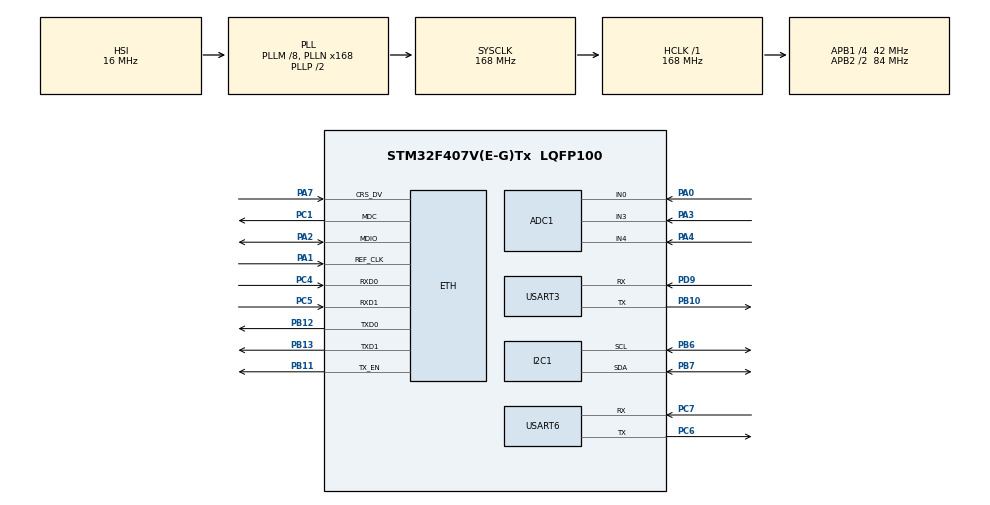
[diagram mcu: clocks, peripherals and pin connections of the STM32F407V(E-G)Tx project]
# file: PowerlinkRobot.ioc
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ADC1.Channel-0\#ChannelRegularConversion=ADC_CHANNEL_TEMPSENSOR
ADC1.NbrOfConversionFlag=1
ADC1.Rank-0\#ChannelRegularConversion=1
ADC1.SamplingTime-0\#ChannelRegularConversion=ADC_SAMPLETIME_3CYCLES
ADC1.master=1
ETH.MediaInterface=ETH_MEDIA_INTERFACE_RMII
FREERTOS.Tasks01=defaultTask,0,128,StartDefaultTask,Default
LWIP.Version=v1.5.0_RC0_20160211_Cube
Mcu.Family=STM32F4
Mcu.Name=STM32F407V(E-G)Tx
Mcu.Package=LQFP100
NVIC.ETH_IRQn=true\:5\:0\:false\:false\:true\:true
NVIC.PriorityGroup=NVIC_PRIORITYGROUP_4
PA0-WKUP.Signal=ADCx_IN0
PA1.Mode=RMII
PA1.Signal=ETH_REF_CLK
PA2.Mode=RMII
PA2.Signal=ETH_MDIO
PA3.Signal=ADCx_IN3
PA4.Signal=ADCx_IN4
PA7.Mode=RMII
PA7.Signal=ETH_CRS_DV
PB10.Mode=Asynchronous
PB10.Signal=USART3_TX
PB11.Mode=RMII
PB11.Signal=ETH_TX_EN
PB12.Mode=RMII
PB12.Signal=ETH_TXD0
PB13.Mode=RMII
PB13.Signal=ETH_TXD1
PB6.Mode=I2C
PB6.Signal=I2C1_SCL
PB7.Mode=I2C
PB7.Signal=I2C1_SDA
PC1.Mode=RMII
PC1.Signal=ETH_MDC
PC4.Mode=RMII
PC4.Signal=ETH_RXD0
PC5.Mode=RMII
PC5.Signal=ETH_RXD1
PC6.Mode=Asynchronous
PC6.Signal=USART6_TX
PC7.Mode=Asynchronous
PC7.Signal=USART6_RX
PD9.Mode=Asynchronous
PD9.Signal=USART3_RX
ProjectManager.HeapSize=0x200
ProjectManager.StackSize=0x400
ProjectManager.TargetToolchain=MDK-ARM V5
RCC.48MHZClocksFreq_Value=84000000
RCC.AHBFreq_Value=168000000
RCC.APB1CLKDivider=RCC_HCLK_DIV4
RCC.APB1Freq_Value=42000000
RCC.APB1TimFreq_Value=84000000
RCC.APB2CLKDivider=RCC_HCLK_DIV2
RCC.APB2Freq_Value=84000000
RCC.APB2TimFreq_Value=168000000
RCC.CortexFreq_Value=168000000
RCC.HCLKFreq_Value=168000000
RCC.HSE_VALUE=25000000
RCC.HSI_VALUE=16000000
RCC.LSE_VALUE=32768
RCC.PLLM=8
RCC.PLLN=168
RCC.SYSCLKFreq_VALUE=168000000
RCC.SYSCLKSource=RCC_SYSCLKSOURCE_PLLCLK
RCC.VCOOutputFreq_Value=336000000
SH.ADCx_IN0.0=ADC1_IN0,IN0
SH.ADCx_IN3.0=ADC1_IN3,IN3
SH.ADCx_IN4.0=ADC1_IN4,IN4
VP_ADC1_TempSens_Input.Mode=IN-TempSens
VP_FREERTOS_VS_ENABLE.Mode=Enabled
VP_LWIP_VS_Enabled.Mode=Enabled
VP_TIM12_VS_ClockSourceINT.Mode=Internal
VP_TIM1_VS_ClockSourceINT.Mode=Internal
VP_TIM2_VS_ClockSourceINT.Mode=Internal
VP_TIM3_VS_ClockSourceINT.Mode=Internal
VP_TIM4_VS_ClockSourceINT.Mode=Internal
VP_TIM5_VS_ClockSourceINT.Mode=Internal
VP_TIM7_VS_ClockSourceINT.Mode=Enable_Timer
VP_TIM8_VS_ClockSourceINT.Mode=Internal
VP_WWDG_VS_WWDG.Mode=WWDG_Activate
board=PowerlinkRobot

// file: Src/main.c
/**
  ******************************************************************************
  * File Name          : main.c
  * Description        : Main program body
  ******************************************************************************
  *
  * COPYRIGHT(c) 2016 STMicroelectronics
  *
  * Redistribution and use in source and binary forms, with or without modification,
  * are permitted provided that the following conditions are met:
  *   1. Redistributions of source code must retain the above copyright notice,
  *      this list of conditions and the following disclaimer.
  *   2. Redistributions in binary form must reproduce the above copyright notice,
  *      this list of conditions and the following disclaimer in the documentation
  *      and/or other materials provided with the distribution.
  *   3. Neither the name of STMicroelectronics nor the names of its contributors
  *      may be used to endorse or promote products derived from this software
  *      without specific prior written permission.
  *
  * THIS SOFTWARE IS PROVIDED BY THE COPYRIGHT HOLDERS AND CONTRIBUTORS "AS IS"
  * AND ANY EXPRESS OR IMPLIED WARRANTIES, INCLUDING, BUT NOT LIMITED TO, THE
  * IMPLIED WARRANTIES OF MERCHANTABILITY AND FITNESS FOR A PARTICULAR PURPOSE ARE
  * DISCLAIMED. IN NO EVENT SHALL THE COPYRIGHT HOLDER OR CONTRIBUTORS BE LIABLE
  * FOR ANY DIRECT, INDIRECT, INCIDENTAL, SPECIAL, EXEMPLARY, OR CONSEQUENTIAL
  * DAMAGES (INCLUDING, BUT NOT LIMITED TO, PROCUREMENT OF SUBSTITUTE GOODS OR
  * SERVICES; LOSS OF USE, DATA, OR PROFITS; OR BUSINESS INTERRUPTION) HOWEVER
  * CAUSED AND ON ANY THEORY OF LIABILITY, WHETHER IN CONTRACT, STRICT LIABILITY,
  * OR TORT (INCLUDING NEGLIGENCE OR OTHERWISE) ARISING IN ANY WAY OUT OF THE USE
  * OF THIS SOFTWARE, EVEN IF ADVISED OF THE POSSIBILITY OF SUCH DAMAGE.
  *
  ******************************************************************************
  */
#include "stm32f4xx_hal.h"
#include "cmsis_os.h"
/* USER CODE BEGIN Includes */
#include "eplTask.h"
/* USER CODE END Includes */

ADC_HandleTypeDef hadc1;

I2C_HandleTypeDef hi2c1;

TIM_HandleTypeDef htim1;
TIM_HandleTypeDef htim2;
TIM_HandleTypeDef htim3;
TIM_HandleTypeDef htim4;
TIM_HandleTypeDef htim5;
TIM_HandleTypeDef htim7;
TIM_HandleTypeDef htim8;
TIM_HandleTypeDef htim12;

UART_HandleTypeDef huart3;
UART_HandleTypeDef huart6;

WWDG_HandleTypeDef hwwdg;

osThreadId defaultTaskHandle;

/* USER CODE BEGIN PV */
/* Private variables ---------------------------------------------------------*/

/* USER CODE END PV */

void SystemClock_Config(void);
void Error_Handler(void);
static void MX_GPIO_Init(void);
static void MX_ADC1_Init(void);
static void MX_I2C1_Init(void);
static void MX_TIM1_Init(void);
static void MX_TIM2_Init(void);
static void MX_TIM3_Init(void);
static void MX_TIM4_Init(void);
static void MX_TIM5_Init(void);
static void MX_TIM7_Init(void);
static void MX_TIM8_Init(void);
static void MX_TIM12_Init(void);
static void MX_USART3_UART_Init(void);
static void MX_USART6_UART_Init(void);
static void MX_WWDG_Init(void);
void StartDefaultTask(void const * argument);

/* USER CODE BEGIN PFP */
/* Private function prototypes -----------------------------------------------*/

/* USER CODE END PFP */

int main(void)
{

  /* MCU Configuration----------------------------------------------------------*/

  /* Reset of all peripherals, Initializes the Flash interface and the Systick. */
  HAL_Init();

  /* Configure the system clock */
  SystemClock_Config();

  /* Initialize all configured peripherals */
  MX_GPIO_Init();
  MX_ADC1_Init();
  MX_I2C1_Init();
  MX_TIM1_Init();
  MX_TIM2_Init();
  MX_TIM3_Init();
  MX_TIM4_Init();
  MX_TIM5_Init();
  MX_TIM7_Init();
  MX_TIM8_Init();
  MX_TIM12_Init();
  MX_USART3_UART_Init();
  MX_USART6_UART_Init();
  //MX_WWDG_Init();

  /* Create the thread(s) */
  /* definition and creation of defaultTask */
  osThreadDef(defaultTask, StartDefaultTask, osPriorityNormal, 0, 2048);
  defaultTaskHandle = osThreadCreate(osThread(defaultTask), NULL);

  /* Start scheduler */
  osKernelStart();

  /* We should never get here as control is now taken by the scheduler */

  /* Infinite loop */
  while (1)
  {

  }

}

/** System Clock Configuration
*/
void SystemClock_Config(void)
{

  RCC_OscInitTypeDef RCC_OscInitStruct;
  RCC_ClkInitTypeDef RCC_ClkInitStruct;

  __HAL_RCC_PWR_CLK_ENABLE();

  __HAL_PWR_VOLTAGESCALING_CONFIG(PWR_REGULATOR_VOLTAGE_SCALE1);

  RCC_OscInitStruct.OscillatorType = RCC_OSCILLATORTYPE_HSI;
  RCC_OscInitStruct.HSIState = RCC_HSI_ON;
  RCC_OscInitStruct.HSICalibrationValue = 16;
  RCC_OscInitStruct.PLL.PLLState = RCC_PLL_ON;
  RCC_OscInitStruct.PLL.PLLSource = RCC_PLLSOURCE_HSI;
  RCC_OscInitStruct.PLL.PLLM = 8;
  RCC_OscInitStruct.PLL.PLLN = 168;
  RCC_OscInitStruct.PLL.PLLP = RCC_PLLP_DIV2;
  RCC_OscInitStruct.PLL.PLLQ = 4;
  if (HAL_RCC_OscConfig(&RCC_OscInitStruct) != HAL_OK)
  {
    Error_Handler();
  }

  RCC_ClkInitStruct.ClockType = RCC_CLOCKTYPE_HCLK|RCC_CLOCKTYPE_SYSCLK
                              |RCC_CLOCKTYPE_PCLK1|RCC_CLOCKTYPE_PCLK2;
  RCC_ClkInitStruct.SYSCLKSource = RCC_SYSCLKSOURCE_PLLCLK;
  RCC_ClkInitStruct.AHBCLKDivider = RCC_SYSCLK_DIV1;
  RCC_ClkInitStruct.APB1CLKDivider = RCC_HCLK_DIV4;
  RCC_ClkInitStruct.APB2CLKDivider = RCC_HCLK_DIV2;
  if (HAL_RCC_ClockConfig(&RCC_ClkInitStruct, FLASH_LATENCY_5) != HAL_OK)
  {
    Error_Handler();
  }

  HAL_SYSTICK_Config(HAL_RCC_GetHCLKFreq()/1000);

  HAL_SYSTICK_CLKSourceConfig(SYSTICK_CLKSOURCE_HCLK);

  /* SysTick_IRQn interrupt configuration */
  HAL_NVIC_SetPriority(SysTick_IRQn, 0, 0);
}

/* ADC1 init function */
static void MX_ADC1_Init(void)
{

  ADC_ChannelConfTypeDef sConfig;

    /**Configure the global features of the ADC (Clock, Resolution, Data Alignment and number of conversion)
    */
  hadc1.Instance = ADC1;
  hadc1.Init.ClockPrescaler = ADC_CLOCK_SYNC_PCLK_DIV4;
  hadc1.Init.Resolution = ADC_RESOLUTION_12B;
  hadc1.Init.ScanConvMode = DISABLE;
  hadc1.Init.ContinuousConvMode = DISABLE;
  hadc1.Init.DiscontinuousConvMode = DISABLE;
  hadc1.Init.ExternalTrigConvEdge = ADC_EXTERNALTRIGCONVEDGE_NONE;
  hadc1.Init.DataAlign = ADC_DATAALIGN_RIGHT;
  hadc1.Init.NbrOfConversion = 1;
  hadc1.Init.DMAContinuousRequests = DISABLE;
  hadc1.Init.EOCSelection = ADC_EOC_SINGLE_CONV;
  if (HAL_ADC_Init(&hadc1) != HAL_OK)
  {
    Error_Handler();
  }

    /**Configure for the selected ADC regular channel its corresponding rank in the sequencer and its sample time.
    */
  sConfig.Channel = ADC_CHANNEL_TEMPSENSOR;
  sConfig.Rank = 1;
  sConfig.SamplingTime = ADC_SAMPLETIME_3CYCLES;
  if (HAL_ADC_ConfigChannel(&hadc1, &sConfig) != HAL_OK)
  {
    Error_Handler();
  }

}

/* I2C1 init function */
static void MX_I2C1_Init(void)
{

  hi2c1.Instance = I2C1;
  hi2c1.Init.ClockSpeed = 100000;
  hi2c1.Init.DutyCycle = I2C_DUTYCYCLE_2;
  hi2c1.Init.OwnAddress1 = 0;
  hi2c1.Init.AddressingMode = I2C_ADDRESSINGMODE_7BIT;
  hi2c1.Init.DualAddressMode = I2C_DUALADDRESS_DISABLE;
  hi2c1.Init.OwnAddress2 = 0;
  hi2c1.Init.GeneralCallMode = I2C_GENERALCALL_DISABLE;
  hi2c1.Init.NoStretchMode = I2C_NOSTRETCH_DISABLE;
  if (HAL_I2C_Init(&hi2c1) != HAL_OK)
  {
    Error_Handler();
  }

}

/* TIM1 init function */
static void MX_TIM1_Init(void)
{

  TIM_ClockConfigTypeDef sClockSourceConfig;
  TIM_MasterConfigTypeDef sMasterConfig;

  htim1.Instance = TIM1;
  htim1.Init.Prescaler = 0;
  htim1.Init.CounterMode = TIM_COUNTERMODE_UP;
  htim1.Init.Period = 0;
  htim1.Init.ClockDivision = TIM_CLOCKDIVISION_DIV1;
  htim1.Init.RepetitionCounter = 0;
  if (HAL_TIM_Base_Init(&htim1) != HAL_OK)
  {
    Error_Handler();
  }

  sClockSourceConfig.ClockSource = TIM_CLOCKSOURCE_INTERNAL;
  if (HAL_TIM_ConfigClockSource(&htim1, &sClockSourceConfig) != HAL_OK)
  {
    Error_Handler();
  }

  sMasterConfig.MasterOutputTrigger = TIM_TRGO_RESET;
  sMasterConfig.MasterSlaveMode = TIM_MASTERSLAVEMODE_DISABLE;
  if (HAL_TIMEx_MasterConfigSynchronization(&htim1, &sMasterConfig) != HAL_OK)
  {
    Error_Handler();
  }

}

/* TIM2 init function */
static void MX_TIM2_Init(void)
{

  TIM_ClockConfigTypeDef sClockSourceConfig;
  TIM_MasterConfigTypeDef sMasterConfig;

  htim2.Instance = TIM2;
  htim2.Init.Prescaler = 0;
  htim2.Init.CounterMode = TIM_COUNTERMODE_UP;
  htim2.Init.Period = 0;
  htim2.Init.ClockDivision = TIM_CLOCKDIVISION_DIV1;
  if (HAL_TIM_Base_Init(&htim2) != HAL_OK)
  {
    Error_Handler();
  }

  sClockSourceConfig.ClockSource = TIM_CLOCKSOURCE_INTERNAL;
  if (HAL_TIM_ConfigClockSource(&htim2, &sClockSourceConfig) != HAL_OK)
  {
    Error_Handler();
  }

  sMasterConfig.MasterOutputTrigger = TIM_TRGO_RESET;
  sMasterConfig.MasterSlaveMode = TIM_MASTERSLAVEMODE_DISABLE;
  if (HAL_TIMEx_MasterConfigSynchronization(&htim2, &sMasterConfig) != HAL_OK)
  {
    Error_Handler();
  }

}

/* TIM3 init function */
static void MX_TIM3_Init(void)
{

  TIM_ClockConfigTypeDef sClockSourceConfig;
  TIM_MasterConfigTypeDef sMasterConfig;

  htim3.Instance = TIM3;
  htim3.Init.Prescaler = 0;
  htim3.Init.CounterMode = TIM_COUNTERMODE_UP;
  htim3.Init.Period = 0;
  htim3.Init.ClockDivision = TIM_CLOCKDIVISION_DIV1;
  if (HAL_TIM_Base_Init(&htim3) != HAL_OK)
  {
    Error_Handler();
  }

  sClockSourceConfig.ClockSource = TIM_CLOCKSOURCE_INTERNAL;
  if (HAL_TIM_ConfigClockSource(&htim3, &sClockSourceConfig) != HAL_OK)
  {
    Error_Handler();
  }

  sMasterConfig.MasterOutputTrigger = TIM_TRGO_RESET;
  sMasterConfig.MasterSlaveMode = TIM_MASTERSLAVEMODE_DISABLE;
  if (HAL_TIMEx_MasterConfigSynchronization(&htim3, &sMasterConfig) != HAL_OK)
  {
    Error_Handler();
  }

}

/* TIM4 init function */
static void MX_TIM4_Init(void)
{

  TIM_ClockConfigTypeDef sClockSourceConfig;
  TIM_MasterConfigTypeDef sMasterConfig;

  htim4.Instance = TIM4;
  htim4.Init.Prescaler = 0;
  htim4.Init.CounterMode = TIM_COUNTERMODE_UP;
  htim4.Init.Period = 0;
  htim4.Init.ClockDivision = TIM_CLOCKDIVISION_DIV1;
  if (HAL_TIM_Base_Init(&htim4) != HAL_OK)
  {
    Error_Handler();
  }

  sClockSourceConfig.ClockSource = TIM_CLOCKSOURCE_INTERNAL;
  if (HAL_TIM_ConfigClockSource(&htim4, &sClockSourceConfig) != HAL_OK)
  {
    Error_Handler();
  }

  sMasterConfig.MasterOutputTrigger = TIM_TRGO_RESET;
  sMasterConfig.MasterSlaveMode = TIM_MASTERSLAVEMODE_DISABLE;
  if (HAL_TIMEx_MasterConfigSynchronization(&htim4, &sMasterConfig) != HAL_OK)
  {
    Error_Handler();
  }

}

/* TIM5 init function */
static void MX_TIM5_Init(void)
{

  TIM_ClockConfigTypeDef sClockSourceConfig;
  TIM_MasterConfigTypeDef sMasterConfig;

  htim5.Instance = TIM5;
  htim5.Init.Prescaler = 0;
  htim5.Init.CounterMode = TIM_COUNTERMODE_UP;
  htim5.Init.Period = 0;
  htim5.Init.ClockDivision = TIM_CLOCKDIVISION_DIV1;
  if (HAL_TIM_Base_Init(&htim5) != HAL_OK)
  {
    Error_Handler();
  }

  sClockSourceConfig.ClockSource = TIM_CLOCKSOURCE_INTERNAL;
  if (HAL_TIM_ConfigClockSource(&htim5, &sClockSourceConfig) != HAL_OK)
  {
    Error_Handler();
  }

  sMasterConfig.MasterOutputTrigger = TIM_TRGO_RESET;
  sMasterConfig.MasterSlaveMode = TIM_MASTERSLAVEMODE_DISABLE;
  if (HAL_TIMEx_MasterConfigSynchronization(&htim5, &sMasterConfig) != HAL_OK)
  {
    Error_Handler();
  }

}

/* TIM7 init function */
static void MX_TIM7_Init(void)
{

  TIM_MasterConfigTypeDef sMasterConfig;

  htim7.Instance = TIM7;
  htim7.Init.Prescaler = 0;
  htim7.Init.CounterMode = TIM_COUNTERMODE_UP;
  htim7.Init.Period = 0;
  if (HAL_TIM_Base_Init(&htim7) != HAL_OK)
  {
    Error_Handler();
  }

  sMasterConfig.MasterOutputTrigger = TIM_TRGO_RESET;
  sMasterConfig.MasterSlaveMode = TIM_MASTERSLAVEMODE_DISABLE;
  if (HAL_TIMEx_MasterConfigSynchronization(&htim7, &sMasterConfig) != HAL_OK)
  {
    Error_Handler();
  }

}

/* TIM8 init function */
static void MX_TIM8_Init(void)
{

  TIM_ClockConfigTypeDef sClockSourceConfig;
  TIM_MasterConfigTypeDef sMasterConfig;

  htim8.Instance = TIM8;
  htim8.Init.Prescaler = 0;
  htim8.Init.CounterMode = TIM_COUNTERMODE_UP;
  htim8.Init.Period = 0;
  htim8.Init.ClockDivision = TIM_CLOCKDIVISION_DIV1;
  htim8.Init.RepetitionCounter = 0;
  if (HAL_TIM_Base_Init(&htim8) != HAL_OK)
  {
    Error_Handler();
  }

  sClockSourceConfig.ClockSource = TIM_CLOCKSOURCE_INTERNAL;
  if (HAL_TIM_ConfigClockSource(&htim8, &sClockSourceConfig) != HAL_OK)
  {
    Error_Handler();
  }

  sMasterConfig.MasterOutputTrigger = TIM_TRGO_RESET;
  sMasterConfig.MasterSlaveMode = TIM_MASTERSLAVEMODE_DISABLE;
  if (HAL_TIMEx_MasterConfigSynchronization(&htim8, &sMasterConfig) != HAL_OK)
  {
    Error_Handler();
  }

}

/* TIM12 init function */
static void MX_TIM12_Init(void)
{

  TIM_ClockConfigTypeDef sClockSourceConfig;

  htim12.Instance = TIM12;
  htim12.Init.Prescaler = 0;
  htim12.Init.CounterMode = TIM_COUNTERMODE_UP;
  htim12.Init.Period = 0;
  htim12.Init.ClockDivision = TIM_CLOCKDIVISION_DIV1;
  if (HAL_TIM_Base_Init(&htim12) != HAL_OK)
  {
    Error_Handler();
  }

  sClockSourceConfig.ClockSource = TIM_CLOCKSOURCE_INTERNAL;
  if (HAL_TIM_ConfigClockSource(&htim12, &sClockSourceConfig) != HAL_OK)
  {
    Error_Handler();
  }

}

/* USART3 init function */
static void MX_USART3_UART_Init(void)
{

  huart3.Instance = USART3;
  huart3.Init.BaudRate = 115200;
  huart3.Init.WordLength = UART_WORDLENGTH_8B;
  huart3.Init.StopBits = UART_STOPBITS_1;
  huart3.Init.Parity = UART_PARITY_NONE;
  huart3.Init.Mode = UART_MODE_TX_RX;
  huart3.Init.HwFlowCtl = UART_HWCONTROL_NONE;
  huart3.Init.OverSampling = UART_OVERSAMPLING_16;
  if (HAL_UART_Init(&huart3) != HAL_OK)
  {
    Error_Handler();
  }

}

/* USART6 init function */
static void MX_USART6_UART_Init(void)
{

  huart6.Instance = USART6;
  huart6.Init.BaudRate = 115200;
  huart6.Init.WordLength = UART_WORDLENGTH_8B;
  huart6.Init.StopBits = UART_STOPBITS_1;
  huart6.Init.Parity = UART_PARITY_NONE;
  huart6.Init.Mode = UART_MODE_TX_RX;
  huart6.Init.HwFlowCtl = UART_HWCONTROL_NONE;
  huart6.Init.OverSampling = UART_OVERSAMPLING_16;
  if (HAL_UART_Init(&huart6) != HAL_OK)
  {
    Error_Handler();
  }

}

/* WWDG init function */
static void MX_WWDG_Init(void)
{

  hwwdg.Instance = WWDG;
  hwwdg.Init.Prescaler = WWDG_PRESCALER_1;
  hwwdg.Init.Window = 64;
  hwwdg.Init.Counter = 64;
  hwwdg.Init.EWIMode = WWDG_EWI_DISABLE;
  if (HAL_WWDG_Init(&hwwdg) != HAL_OK)
  {
    Error_Handler();
  }

}

/** Pinout Configuration
*/
static void MX_GPIO_Init(void)
{

  /* GPIO Ports Clock Enable */
  __HAL_RCC_GPIOC_CLK_ENABLE();
  __HAL_RCC_GPIOA_CLK_ENABLE();
  __HAL_RCC_GPIOB_CLK_ENABLE();
  __HAL_RCC_GPIOD_CLK_ENABLE();

}

#include "EdrvF407.h"
#include "Epl.h"
#include "EplDllk.h"
#include "EplEvent.h"
#include "EplTarget.h"

#include "lwip/init.h"
#include "lwip/netif.h"
#include "ethernetif.h"

/* USER CODE BEGIN 4 */
extern tEplKernel EdrvInit(tEdrvInitParam * pEdrvInitParam_p);
/* USER CODE END 4 */

/* StartDefaultTask function */
void StartDefaultTask(void const * argument)
{
  /* init code for LWIP */
  Epl_Init();
	//MX_LWIP_Init();

	//EdrvInit(NULL);

  for(;;)
  {
    osDelay(1);
  }
}

void Error_Handler(void)
{
  while(1)
  {
  }
}

/************************ (C) COPYRIGHT STMicroelectronics *****END OF FILE****/
